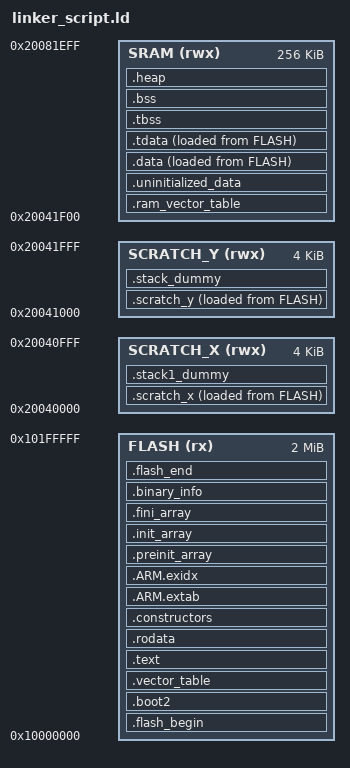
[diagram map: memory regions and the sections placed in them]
MEMORY {
  FLASH(rx) : ORIGIN = 0x10000000, LENGTH = 2048K 
  SRAM(rwx) : ORIGIN = 0x20041f00, LENGTH = 256K
  SCRATCH_X(rwx) : ORIGIN = 0x20040000, LENGTH = 4K 
  SCRATCH_Y(rwx) : ORIGIN = 0x20041000, LENGTH = 4K
}

SECTIONS
{
  .flash_begin : {
    __flash_binary_start = .;
  } > FLASH

  .boot2 : {
    __boot2_start = .;
    KEEP(*(.boot2))
    __boot2_end = .;
  } > FLASH

  ASSERT(__boot2_end - __boot2_start == 256, 
     "Pico second stage bootloader must be 256 bytes in size") 

  .vector_table : 
  {
    __logical_binary_start = .;
    . = ALIGN(4);
    KEEP(*(.vectors))
    KEEP(*(.binary_info_header))
    __binary_info_header_end = .;
    KEEP(*(.embedded_block))
    __embedded_block_end = .;
    KEEP(*(.reset))
    . = ALIGN(4);
  } > FLASH 

  .text : 
  {
    . = ALIGN(4); 
    *(EXCLUDE_FILE(*libgcc.a: *libc.a:*lib_a-mem*.o *libm.a:) .text*)
    /* some of text sections would be better in RAM */ 
    *(.text) 
    *(.text*)
    *(.glue_7)
    *(.glue_7t)
    *(.eh_frame*)
    *(.init)
    *(.fini)
    . = ALIGN(4);
  } > FLASH

  .rodata : 
  {
    *(EXCLUDE_FILE(*libgcc.a: *libc.a:*lib_a-mem*.o *libm.a:) .rodata*)
    . = ALIGN(4);
    *(.rodata)
    *(SORT_BY_ALIGNMENT(SORT_BY_NAME(.flashdata*)))
    *(.rodata*)
    . = ALIGN(4); 
  } > FLASH 

  .constructors : 
  {
    *crtbegin.o(.ctors)
    *crtbegin?.o(.ctors)
    *(EXCLUDE_FILE(*crtend?.o *crtend.o) .ctors)
    *(SORT(.ctors.*))
    *(.ctors)
    *crtbegin.o(.dtors)
    *crtbegin?.o(.dtors)
    *(EXCLUDE_FILE(*crtend?.o *crtend.o) .dtors)
    *(SORT(.dtors.*))
    *(.dtors)
  } > FLASH

  /* ARM exception handling */ 
  .ARM.extab : 
  {
    *(.ARM.extab* .gnu.linkonce.armextab.*) 
  } > FLASH
  .ARM.exidx : 
  {
    __exidx_start = .;
    *(.ARM.exidx*)
    __exidx_end = .; 
  } > FLASH 

  .preinit_array :
  {
    . = ALIGN(4);
    PROVIDE_HIDDEN(__preinit_array_start = .);
    KEEP(*(SORT(.preinit_array.*)))
    KEEP(*(.preinit_array))
    PROVIDE_HIDDEN(__preinit_array_end = .);
  } > FLASH

  .init_array :
  {
    . = ALIGN(4);
    PROVIDE_HIDDEN(__init_array_start = .);
    KEEP(*(SORT(.init_array.*)))
    KEEP(*(.init_array))
    PROVIDE_HIDDEN(__init_array_end = .);
  } > FLASH

  .fini_array : 
  {
    . = ALIGN(4);
    PROVIDE_HIDDEN(__fini_array_start = .);
    KEEP(*(SORT(.fini_array.*)))
    KEEP(*(.fini_array))
    PROVIDE_HIDDEN(__fini_array_end = .);
  } > FLASH

  /* Machine inspectable binary information */
  . = ALIGN(4);
  __binary_info_start = .;
  .binary_info :
  {
    KEEP(*(.binary_info.keep.*))
    *(.binary_info.*)
  } > FLASH
  __binary_info_end = .;
  . = ALIGN(4);
  .ram_vector_table (NOLOAD): {
    *(.ram_vector_table)
  } > SRAM

  .uninitialized_data (NOLOAD) : {
    . = ALIGN(4);
    *(.uninitialized_data*)
  } > SRAM 
   .data : {
        __data_start__ = .;
        *(vtable)

        *(.time_critical*)

        /* remaining .text and .rodata; i.e. stuff we exclude above because we want it in RAM */
        *(.text*)
        . = ALIGN(4);
        *(.rodata*)
        . = ALIGN(4);

        *(.data*)

        . = ALIGN(4);
        *(.after_data.*)
        . = ALIGN(4);
        /* preinit data */
        PROVIDE_HIDDEN (__mutex_array_start = .);
        KEEP(*(SORT(.mutex_array.*)))
        KEEP(*(.mutex_array))
        PROVIDE_HIDDEN (__mutex_array_end = .);

        . = ALIGN(4);
        *(.jcr)
        . = ALIGN(4);
    } > SRAM AT> FLASH

    .tdata : {
        . = ALIGN(4);
		*(.tdata .tdata.* .gnu.linkonce.td.*)
        /* All data end */
        __tdata_end = .;
    } > SRAM AT> FLASH
    PROVIDE(__data_end__ = .);

    /* __etext is (for backwards compatibility) the name of the .data init source pointer (...) */
    __etext = LOADADDR(.data);

    .tbss (NOLOAD) : {
        . = ALIGN(4);
        __bss_start__ = .;
        __tls_base = .;
        *(.tbss .tbss.* .gnu.linkonce.tb.*)
        *(.tcommon)

        __tls_end = .;
    } > SRAM

    .bss (NOLOAD) : {
        . = ALIGN(4);
        __tbss_end = .;

        *(SORT_BY_ALIGNMENT(SORT_BY_NAME(.bss*)))
        *(COMMON)
        . = ALIGN(4);
        __bss_end__ = .;
    } > SRAM

    .heap (NOLOAD):
    {
        __end__ = .;
        end = __end__;
        KEEP(*(.heap*))
    } > SRAM
    /* historically on GCC sbrk was growing past __HeapLimit to __StackLimit, however
       to be more compatible, we now set __HeapLimit explicitly to where the end of the heap is */
    __HeapLimit = ORIGIN(SRAM) + LENGTH(SRAM);

    /* Start and end symbols must be word-aligned */
    .scratch_x : {
        __scratch_x_start__ = .;
        *(.scratch_x.*)
        . = ALIGN(4);
        __scratch_x_end__ = .;
    } > SCRATCH_X AT > FLASH
    __scratch_x_source__ = LOADADDR(.scratch_x);

    .scratch_y : {
        __scratch_y_start__ = .;
        *(.scratch_y.*)
        . = ALIGN(4);
        __scratch_y_end__ = .;
    } > SCRATCH_Y AT > FLASH
    __scratch_y_source__ = LOADADDR(.scratch_y);

    /* .stack*_dummy section doesn't contains any symbols. It is only
     * used for linker to calculate size of stack sections, and assign
     * values to stack symbols later
     *
     * stack1 section may be empty/missing if platform_launch_core1 is not used */

    /* by default we put core 0 stack at the end of scratch Y, so that if core 1
     * stack is not used then all of SCRATCH_X is free.
     */
    .stack1_dummy (NOLOAD):
    {
        *(.stack1*)
    } > SCRATCH_X
    .stack_dummy (NOLOAD):
    {
        KEEP(*(.stack*))
    } > SCRATCH_Y

    .flash_end : {
        KEEP(*(.embedded_end_block*))
        PROVIDE(__flash_binary_end = .);
    } > FLASH

    /* stack limit is poorly named, but historically is maximum heap ptr */
    __StackLimit = ORIGIN(SRAM) + LENGTH(SRAM);
    __StackOneTop = ORIGIN(SCRATCH_X) + LENGTH(SCRATCH_X);
    __StackTop = ORIGIN(SCRATCH_Y) + LENGTH(SCRATCH_Y);
    __StackOneBottom = __StackOneTop - SIZEOF(.stack1_dummy);
    __StackBottom = __StackTop - SIZEOF(.stack_dummy);
    PROVIDE(__stack = __StackTop);

    /* picolibc and LLVM */
    PROVIDE (__heap_start = __end__);
    PROVIDE (__heap_end = __HeapLimit);
    PROVIDE( __tls_align = MAX(ALIGNOF(.tdata), ALIGNOF(.tbss)) );
    PROVIDE( __tls_size_align = (__tls_size + __tls_align - 1) & ~(__tls_align - 1));
    PROVIDE( __arm32_tls_tcb_offset = MAX(8, __tls_align) );

    /* llvm-libc */
    PROVIDE (_end = __end__);
    PROVIDE (__llvm_libc_heap_limit = __HeapLimit);

    /* Check if data + heap + stack exceeds RAM limit */
    ASSERT(__StackLimit >= __HeapLimit, "region RAM overflowed")

    ASSERT( __binary_info_header_end - __logical_binary_start <= 256, "Binary info must be in first 256 bytes of the binary")
    /* todo assert on extra code */
}
